# ipro6s register map
Vendor: intelpro; Series: IPRO6S
CPU: ipro6s, little endian
Registers are 32-bit, read-write, reset 0x0 unless marked. A register's access mark holds for its fields unless they carry their own. Offsets are from the block's base; [hi:lo] are bit positions; {n}, {i} and the like mark numbered series.

## LTMR
Base 0x30011000
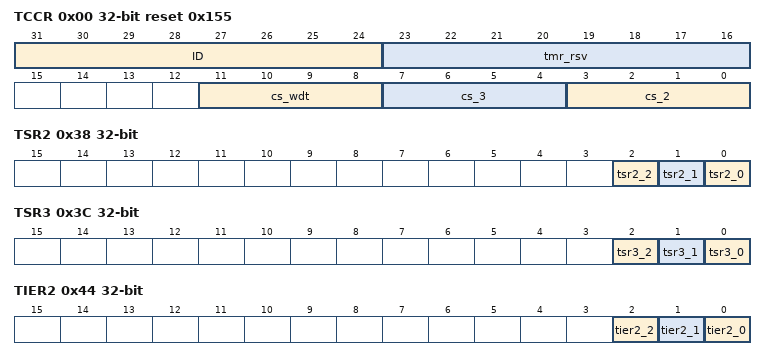
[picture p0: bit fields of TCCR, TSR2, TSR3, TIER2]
0x00 TCCR reset 0x155 (reset mask 0xFF0FFF) — Timer Clock Source
  [31:24] ID ro
  [23:16] tmr_rsv
  [11:8] cs_wdt — WDT 0:fclk / 1:f32k / 2:1k / 3:32M / 4:GPIO / 5:No clock
  [7:4] cs_3 — Timer3 0:fclk / 1:f32k / 2:1k / 3:32M / 4:GPIO / 5:No clock
  [3:0] cs_2 — Timer2 0:fclk / 1:f32k / 2:1k / 3:32M / 4:GPIO / 5:No clock
{0x10+4i} TMR2_{i} reset 0xFFFFFFFF (i=0..2) — Timer2 Match Value {i}
{0x1C+4i} TMR3_{i} reset 0xFFFFFFFF (i=0..2) — Timer3 Match Value {i}
0x2C TCR2 reset not defined — Timer2 Counter Value
  [31:0] tcr2_cnt ro
0x30 TCR3 reset not defined — Timer3 Counter Value
  [31:0] tcr3_cnt ro
0x38 TSR2 reset not defined — Timer2 Match Status
  [2] tsr2_2 ro — Timer2 match value 2 status/Clear interrupt would also clear this bit
  [1] tsr2_1 ro — Timer2 match value 1 status/Clear interrupt would also clear this bit
  [0] tsr2_0 ro — Timer2 match value 0 status/Clear interrupt would also clear this bit
0x3C TSR3 reset not defined — Timer3 Match Status
  [2] tsr3_2 ro — Timer3 match value 2 status/Clear interrupt would also clear this bit
  [1] tsr3_1 ro — Timer3 match value 1 status/Clear interrupt would also clear this bit
  [0] tsr3_0 ro — Timer3 match value 0 status/Clear interrupt would also clear this bit
0x44 TIER2 — Timer2 Match Interrupt Enable
  [2] tier2_2 — Timer2 match value 2 interrupt enable
  [1] tier2_1 — Timer2 match value 1 interrupt enable
  [0] tier2_0 — Timer2 match value 0 interrupt enable
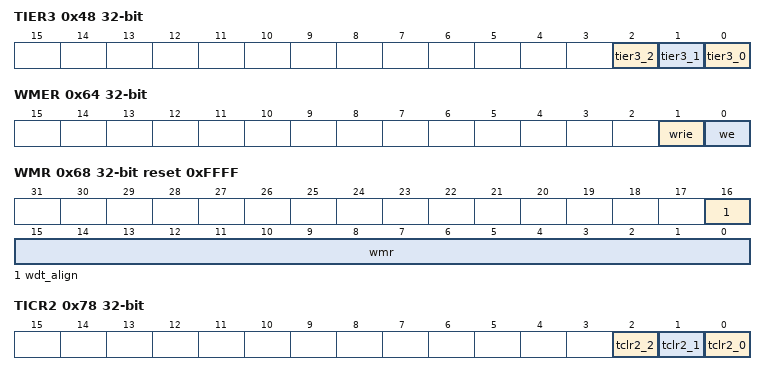
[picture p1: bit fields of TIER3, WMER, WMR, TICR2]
0x48 TIER3 — Timer3 Match Interrupt Enable
  [2] tier3_2 — Timer3 match value 2 interrupt enable
  [1] tier3_1 — Timer3 match value 1 interrupt enable
  [0] tier3_0 — Timer3 match value 0 interrupt enable
0x50 TPLVR2 — Timer2 Pre-Load Value
0x54 TPLVR3 — Timer3 Pre-Load Value
0x5C TPLCR2 — Timer2 Pre-Load Control
  [1:0] tplcr2 — Timer2 pre-load control 2'd0 - No pre-load 2'd1 - Pre-load with match comparator 0 2'd2 - Pre-load with match comparator 1 2'd3 - Pre-load with match comparator 2
0x60 TPLCR3 — Timer3 Pre-Load Control
  [1:0] tplcr3 — Timer3 pre-load control 2'd0 - No pre-load 2'd1 - Pre-load with match comparator 0 2'd2 - Pre-load with match comparator 1 2'd3 - Pre-load with match comparator 2
0x64 WMER — Watch-dog reset/interrupt Mode
  [1] wrie — WDT reset/interrupt mode 1'b0 - WDT expiration to generate interrupt 1'b1 - WDT expiration to generate reset source
  [0] we — WDT enable register
0x68 WMR reset 0xFFFF — Watch-dog Match Value
  [16] wdt_align — WDT compare value update align interrupt
  [15:0] wmr — WDT counter match value
0x6C WVR reset not defined — Watch-dog Counter Value
  [15:0] wdt_cnt ro — WDT counter value
0x70 WSR — Watch-dog Reset Status
  [0] wts wo — WDT reset status Write 0 to clear the WDT reset status Read 1 indicates reset was caused by the WDT
0x78 TICR2 — Timer2 Interrupt Clear
  [2] tclr2_2 wo — Timer2 Interrupt clear for match comparator 2
  [1] tclr2_1 wo — Timer2 Interrupt clear for match comparator 1
  [0] tclr2_0 wo — Timer2 Interrupt clear for match comparator 0
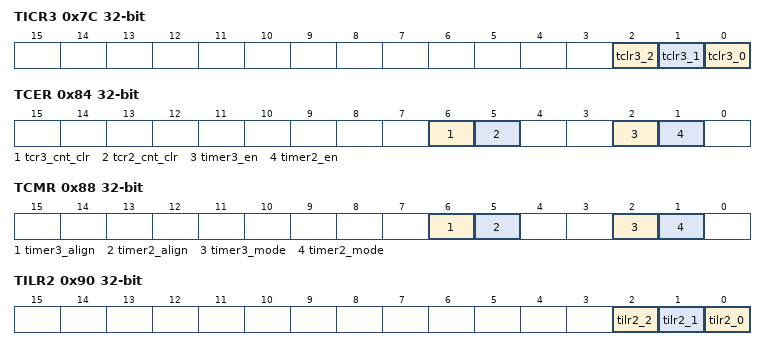
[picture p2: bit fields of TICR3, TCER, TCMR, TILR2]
0x7C TICR3 — Timer3 Interrupt Clear
  [2] tclr3_2 wo — Timer3 Interrupt clear for match comparator 2
  [1] tclr3_1 wo — Timer3 Interrupt clear for match comparator 1
  [0] tclr3_0 wo — Timer3 Interrupt clear for match comparator 0
0x80 WICR — WDT Interrupt Clear
  [0] wiclr wo
0x84 TCER — Timer Counter Enable/Clear
  [6] tcr3_cnt_clr — Timer3 count clear
  [5] tcr2_cnt_clr — Timer2 count clear
  [2] timer3_en — Timer3 count enable
  [1] timer2_en — Timer2 count enable
0x88 TCMR — Timer Counter Mode
  [6] timer3_align — Timer3 compare value update align interrupt
  [5] timer2_align — Timer2 compare value update align interrupt
  [2] timer3_mode — 0:pre-load mode 1:free run mode
  [1] timer2_mode — 0:pre-load mode 1:free run mode
0x90 TILR2 — Timer2 Match Interrupt Mode
  [2] tilr2_2 — 0:level 1:edge
  [1] tilr2_1 — 0:level 1:edge
  [0] tilr2_0 — 0:level 1:edge
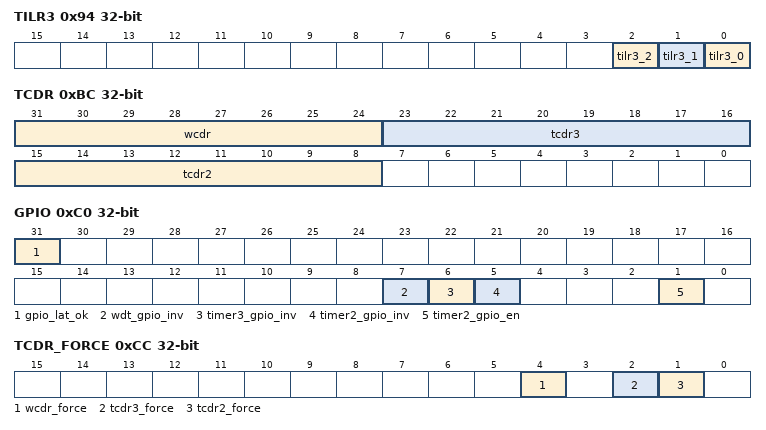
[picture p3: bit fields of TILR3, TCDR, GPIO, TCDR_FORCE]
0x94 TILR3 — Timer3 Match Interrupt Mode
  [2] tilr3_2 — 0:level 1:edge
  [1] tilr3_1 — 0:level 1:edge
  [0] tilr3_0 — 0:level 1:edge
0x98 WCR — WDT Counter Reset
  [0] wcr wo
0x9C WFAR — WDT Access Key1
  [15:0] wfar wo — WDT access key1 - 16'hBABA
0xA0 WSAR — WDT Access Key2
  [15:0] wsar wo — WDT access key2 - 16'hEB10
0xA8 TCVWR2 reset not defined — Timer2 Counter Latch Value
  [31:0] tcr2_cnt_lat ro
0xAC TCVWR3 reset not defined — Timer3 Counter Latch Value
  [31:0] tcr3_cnt_lat ro
0xB4 TCVSYN2 reset not defined — Timer2 Counter Sync Value
  [31:0] tcr2_cnt_sync ro — Timer2 Counter Sync Value (continue readable)
0xB8 TCVSYN3 reset not defined — Timer3 Counter Sync Value
  [31:0] tcr3_cnt_sync ro — Timer3 Counter Sync Value (continue readable)
0xBC TCDR — Timer Division
  [31:24] wcdr — WDT clock division value register
  [23:16] tcdr3 — Timer3 clock division value register
  [15:8] tcdr2 — Timer2 clock division value register
0xC0 GPIO (reset mask 0xE2) — GPIO Mode
  [31] gpio_lat_ok ro — Latch Done. Pulse width = (GPIO_LAT2 - GPIO_LAT1) * (Timer2 Cycle)
  [7] wdt_gpio_inv — WDT gpio polarity 0:pos 1:neg
  [6] timer3_gpio_inv — Timer3 gpio polarity 0:pos 1:neg
  [5] timer2_gpio_inv — Timer2 gpio polarity 0:pos 1:neg
  [1] timer2_gpio_en — Timer2 gpio measure enable
0xC4 GPIO_LAT1 reset not defined — GPIO Latch Value1
  [31:0] gpio_lat1 ro — Pos-Edge Latch Timer2
0xC8 GPIO_LAT2 reset not defined — GPIO Latch Value2
  [31:0] gpio_lat2 ro — Neg-Edge Latch Timer2
0xCC TCDR_FORCE — Timer Division Force
  [4] wcdr_force — Force WDT clock division value to counter
  [2] tcdr3_force — Force Timer3 clock division value to counter
  [1] tcdr2_force — Force Timer2 clock division value to counter
